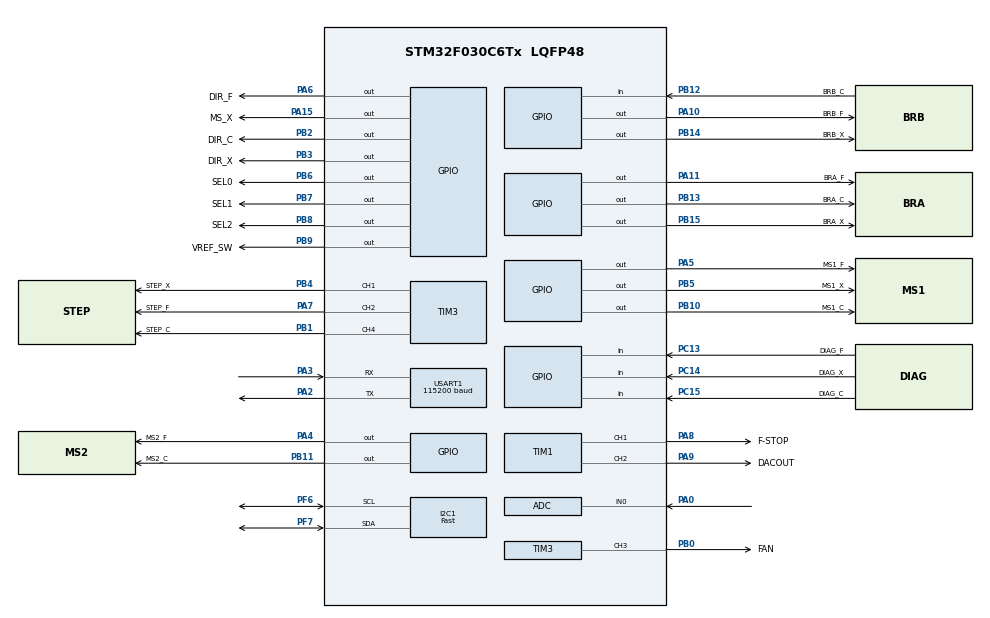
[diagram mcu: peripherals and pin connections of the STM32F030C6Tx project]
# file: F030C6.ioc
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Dma.I2C1_RX.1.Direction=DMA_PERIPH_TO_MEMORY
Dma.I2C1_RX.1.Instance=DMA1_Channel3
Dma.I2C1_RX.1.MemDataAlignment=DMA_MDATAALIGN_BYTE
Dma.I2C1_RX.1.MemInc=DMA_MINC_ENABLE
Dma.I2C1_RX.1.Mode=DMA_NORMAL
Dma.I2C1_RX.1.PeriphDataAlignment=DMA_PDATAALIGN_BYTE
Dma.I2C1_RX.1.PeriphInc=DMA_PINC_DISABLE
Dma.I2C1_RX.1.Priority=DMA_PRIORITY_HIGH
Dma.I2C1_TX.2.Direction=DMA_MEMORY_TO_PERIPH
Dma.I2C1_TX.2.Instance=DMA1_Channel2
Dma.I2C1_TX.2.MemDataAlignment=DMA_MDATAALIGN_BYTE
Dma.I2C1_TX.2.MemInc=DMA_MINC_ENABLE
Dma.I2C1_TX.2.Mode=DMA_NORMAL
Dma.I2C1_TX.2.PeriphDataAlignment=DMA_PDATAALIGN_BYTE
Dma.I2C1_TX.2.PeriphInc=DMA_PINC_DISABLE
Dma.I2C1_TX.2.Priority=DMA_PRIORITY_HIGH
Dma.Request0=USART1_TX
Dma.Request1=I2C1_RX
Dma.Request2=I2C1_TX
Dma.Request3=USART1_RX
Dma.USART1_RX.3.Direction=DMA_PERIPH_TO_MEMORY
Dma.USART1_RX.3.Instance=DMA1_Channel5
Dma.USART1_RX.3.MemDataAlignment=DMA_MDATAALIGN_BYTE
Dma.USART1_RX.3.MemInc=DMA_MINC_ENABLE
Dma.USART1_RX.3.Mode=DMA_NORMAL
Dma.USART1_RX.3.PeriphDataAlignment=DMA_PDATAALIGN_BYTE
Dma.USART1_RX.3.PeriphInc=DMA_PINC_DISABLE
Dma.USART1_RX.3.Priority=DMA_PRIORITY_LOW
Dma.USART1_TX.0.Direction=DMA_MEMORY_TO_PERIPH
Dma.USART1_TX.0.Instance=DMA1_Channel4
Dma.USART1_TX.0.MemDataAlignment=DMA_MDATAALIGN_BYTE
Dma.USART1_TX.0.MemInc=DMA_MINC_ENABLE
Dma.USART1_TX.0.Mode=DMA_NORMAL
Dma.USART1_TX.0.PeriphDataAlignment=DMA_PDATAALIGN_BYTE
Dma.USART1_TX.0.PeriphInc=DMA_PINC_DISABLE
Dma.USART1_TX.0.Priority=DMA_PRIORITY_LOW
I2C1.AddressingMode=I2C_ADDRESSINGMODE_7BIT
I2C1.Analog_Filter=I2C_ANALOGFILTER_DISABLE
I2C1.I2C_Speed_Mode=I2C_Fast
I2C1.OwnAddress=0x24
I2C1.Timing=0x0000020C
Mcu.Family=STM32F0
Mcu.Name=STM32F030C6Tx
Mcu.Package=LQFP48
NVIC.DMA1_Channel2_3_IRQn=true\:0\:0\:false\:false\:true\:false\:true\:true
NVIC.DMA1_Channel4_5_IRQn=true\:0\:0\:false\:false\:true\:false\:true\:true
NVIC.I2C1_IRQn=true\:0\:0\:false\:false\:true\:true\:true\:true
NVIC.TIM17_IRQn=true\:3\:0\:false\:false\:true\:false\:true\:true
NVIC.TimeBase=TIM17_IRQn
NVIC.TimeBaseIP=TIM17
NVIC.USART1_IRQn=true\:0\:0\:false\:false\:true\:true\:true\:true
PA0.Mode=IN0
PA0.Signal=ADC_IN0
PA10.GPIO_Label=BRB_F
PA10.Signal=GPIO_Output
PA11.GPIO_Label=BRA_F
PA11.Signal=GPIO_Output
PA13.Mode=Serial_Wire
PA13.Signal=SYS_SWDIO
PA14.Mode=Serial_Wire
PA14.Signal=SYS_SWCLK
PA15.GPIO_Label=MS_X
PA15.Signal=GPIO_Output
PA2.Mode=Asynchronous
PA2.Signal=USART1_TX
PA3.Mode=Asynchronous
PA3.Signal=USART1_RX
PA4.GPIO_Label=MS2_F
PA4.Signal=GPIO_Output
PA5.GPIO_Label=MS1_F
PA5.Signal=GPIO_Output
PA6.GPIO_Label=DIR_F
PA6.Signal=GPIO_Output
PA7.GPIO_Label=STEP_F
PA7.Signal=S_TIM3_CH2
PA8.GPIO_Label=F-STOP
PA8.Signal=S_TIM1_CH1
PA9.GPIO_Label=DACOUT
PA9.Signal=S_TIM1_CH2
PB0.GPIO_Label=FAN
PB0.Signal=S_TIM3_CH3
PB1.GPIO_Label=STEP_C
PB1.Signal=S_TIM3_CH4
PB10.GPIO_Label=MS1_C
PB10.Signal=GPIO_Output
PB11.GPIO_Label=MS2_C
PB11.Signal=GPIO_Output
PB12.GPIO_Label=BRB_C
PB12.Signal=GPIO_Input
PB13.GPIO_Label=BRA_C
PB13.Signal=GPIO_Output
PB14.GPIO_Label=BRB_X
PB14.Signal=GPIO_Output
PB15.GPIO_Label=BRA_X
PB15.Signal=GPIO_Output
PB2.GPIO_Label=DIR_C
PB2.Signal=GPIO_Output
PB3.GPIO_Label=DIR_X
PB3.Signal=GPIO_Output
PB4.GPIO_Label=STEP_X
PB4.Signal=S_TIM3_CH1
PB5.GPIO_Label=MS1_X
PB5.Signal=GPIO_Output
PB6.GPIO_Label=SEL0
PB6.Signal=GPIO_Output
PB7.GPIO_Label=SEL1
PB7.Signal=GPIO_Output
PB8.GPIO_Label=SEL2
PB8.Signal=GPIO_Output
PB9.GPIO_Label=VREF_SW
PB9.Signal=GPIO_Output
PC13.GPIO_Label=DIAG_F
PC13.Signal=GPIO_Input
PC14-OSC32_IN.GPIO_Label=DIAG_X
PC14-OSC32_IN.Signal=GPIO_Input
PC15-OSC32_OUT.GPIO_Label=DIAG_C
PC15-OSC32_OUT.Signal=GPIO_Input
PF0-OSC_IN.Mode=HSE-External-Oscillator
PF0-OSC_IN.Signal=RCC_OSC_IN
PF1-OSC_OUT.Mode=HSE-External-Oscillator
PF1-OSC_OUT.Signal=RCC_OSC_OUT
PF6.GPIO_Pu=GPIO_PULLUP
PF6.GPIO_Speed=GPIO_SPEED_FREQ_HIGH
PF6.Mode=I2C
PF6.Signal=I2C1_SCL
PF7.GPIO_Pu=GPIO_PULLUP
PF7.GPIO_Speed=GPIO_SPEED_FREQ_HIGH
PF7.Mode=I2C
PF7.Signal=I2C1_SDA
ProjectManager.HeapSize=0x200
ProjectManager.StackSize=0x400
ProjectManager.TargetToolchain=MDK-ARM V5
SH.S_TIM1_CH1.0=TIM1_CH1,PWM Generation1 CH1
SH.S_TIM1_CH2.0=TIM1_CH2,PWM Generation2 CH2
SH.S_TIM3_CH1.0=TIM3_CH1,PWM Generation1 CH1
SH.S_TIM3_CH2.0=TIM3_CH2,PWM Generation2 CH2
SH.S_TIM3_CH3.0=TIM3_CH3,PWM Generation3 CH3
SH.S_TIM3_CH4.0=TIM3_CH4,PWM Generation4 CH4
TIM1.Channel-PWM\ Generation1\ CH1=TIM_CHANNEL_1
TIM1.Channel-PWM\ Generation2\ CH2=TIM_CHANNEL_2
TIM3.Channel-PWM\ Generation1\ CH1=TIM_CHANNEL_1
TIM3.Channel-PWM\ Generation2\ CH2=TIM_CHANNEL_2
TIM3.Channel-PWM\ Generation3\ CH3=TIM_CHANNEL_3
TIM3.Channel-PWM\ Generation4\ CH4=TIM_CHANNEL_4
USART1.BaudRate=115200
USART1.VirtualMode-Asynchronous=VM_ASYNC
VP_SYS_VS_tim17.Mode=TIM17
board=custom

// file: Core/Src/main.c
/* USER CODE BEGIN Header */
/**
  ******************************************************************************
  * @file           : main.c
  * @brief          : Main program body
  ******************************************************************************
  * @attention
  *
  * Copyright (c) 2025 STMicroelectronics.
  * All rights reserved.
  *
  * This software is licensed under terms that can be found in the LICENSE file
  * in the root directory of this software component.
  * If no LICENSE file comes with this software, it is provided AS-IS.
  *
  ******************************************************************************
  */
/* USER CODE END Header */
#include "main.h"
#include "adc.h"
#include "dma.h"
#include "i2c.h"
#include "tim.h"
#include "usart.h"
#include "gpio.h"

/* USER CODE BEGIN Includes */
#include <string.h>
#include "i2c_client.h"
/* USER CODE END Includes */

void SystemClock_Config(void);

int main(void)
{

  /* MCU Configuration--------------------------------------------------------*/

  /* Reset of all peripherals, Initializes the Flash interface and the Systick. */
  HAL_Init();

  /* Configure the system clock */
  SystemClock_Config();

  /* Initialize all configured peripherals */
  MX_GPIO_Init();
  MX_DMA_Init();
  MX_TIM1_Init();
  MX_TIM3_Init();
  MX_USART1_UART_Init();
  MX_ADC_Init();
  MX_I2C1_Init();
  /* USER CODE BEGIN 2 */
  HAL_I2C_EnableListen_IT(&hi2c1);
  HAL_I2C_Slave_Seq_Receive_DMA(&hi2c1, RxData, sizeof(RxData),I2C_FIRST_FRAME);
  /* USER CODE END 2 */

  /* Infinite loop */
  while (1)
  {

  }
}

void SystemClock_Config(void)
{
  RCC_OscInitTypeDef RCC_OscInitStruct = {0};
  RCC_ClkInitTypeDef RCC_ClkInitStruct = {0};
  RCC_PeriphCLKInitTypeDef PeriphClkInit = {0};

  /** Initializes the RCC Oscillators according to the specified parameters
  * in the RCC_OscInitTypeDef structure.
  */
  RCC_OscInitStruct.OscillatorType = RCC_OSCILLATORTYPE_HSI|RCC_OSCILLATORTYPE_HSI14;
  RCC_OscInitStruct.HSIState = RCC_HSI_ON;
  RCC_OscInitStruct.HSI14State = RCC_HSI14_ON;
  RCC_OscInitStruct.HSICalibrationValue = RCC_HSICALIBRATION_DEFAULT;
  RCC_OscInitStruct.HSI14CalibrationValue = 16;
  RCC_OscInitStruct.PLL.PLLState = RCC_PLL_NONE;
  if (HAL_RCC_OscConfig(&RCC_OscInitStruct) != HAL_OK)
  {
    Error_Handler();
  }

  /** Initializes the CPU, AHB and APB buses clocks
  */
  RCC_ClkInitStruct.ClockType = RCC_CLOCKTYPE_HCLK|RCC_CLOCKTYPE_SYSCLK
                              |RCC_CLOCKTYPE_PCLK1;
  RCC_ClkInitStruct.SYSCLKSource = RCC_SYSCLKSOURCE_HSI;
  RCC_ClkInitStruct.AHBCLKDivider = RCC_SYSCLK_DIV1;
  RCC_ClkInitStruct.APB1CLKDivider = RCC_HCLK_DIV1;

  if (HAL_RCC_ClockConfig(&RCC_ClkInitStruct, FLASH_LATENCY_0) != HAL_OK)
  {
    Error_Handler();
  }
  PeriphClkInit.PeriphClockSelection = RCC_PERIPHCLK_USART1|RCC_PERIPHCLK_I2C1;
  PeriphClkInit.Usart1ClockSelection = RCC_USART1CLKSOURCE_PCLK1;
  PeriphClkInit.I2c1ClockSelection = RCC_I2C1CLKSOURCE_HSI;
  if (HAL_RCCEx_PeriphCLKConfig(&PeriphClkInit) != HAL_OK)
  {
    Error_Handler();
  }
}

void HAL_TIM_PeriodElapsedCallback(TIM_HandleTypeDef *htim)
{
  if (htim->Instance == TIM17) {
    HAL_IncTick();
  }
}

void Error_Handler(void)
{
  __disable_irq();
  while (1)
  {
  }
}
